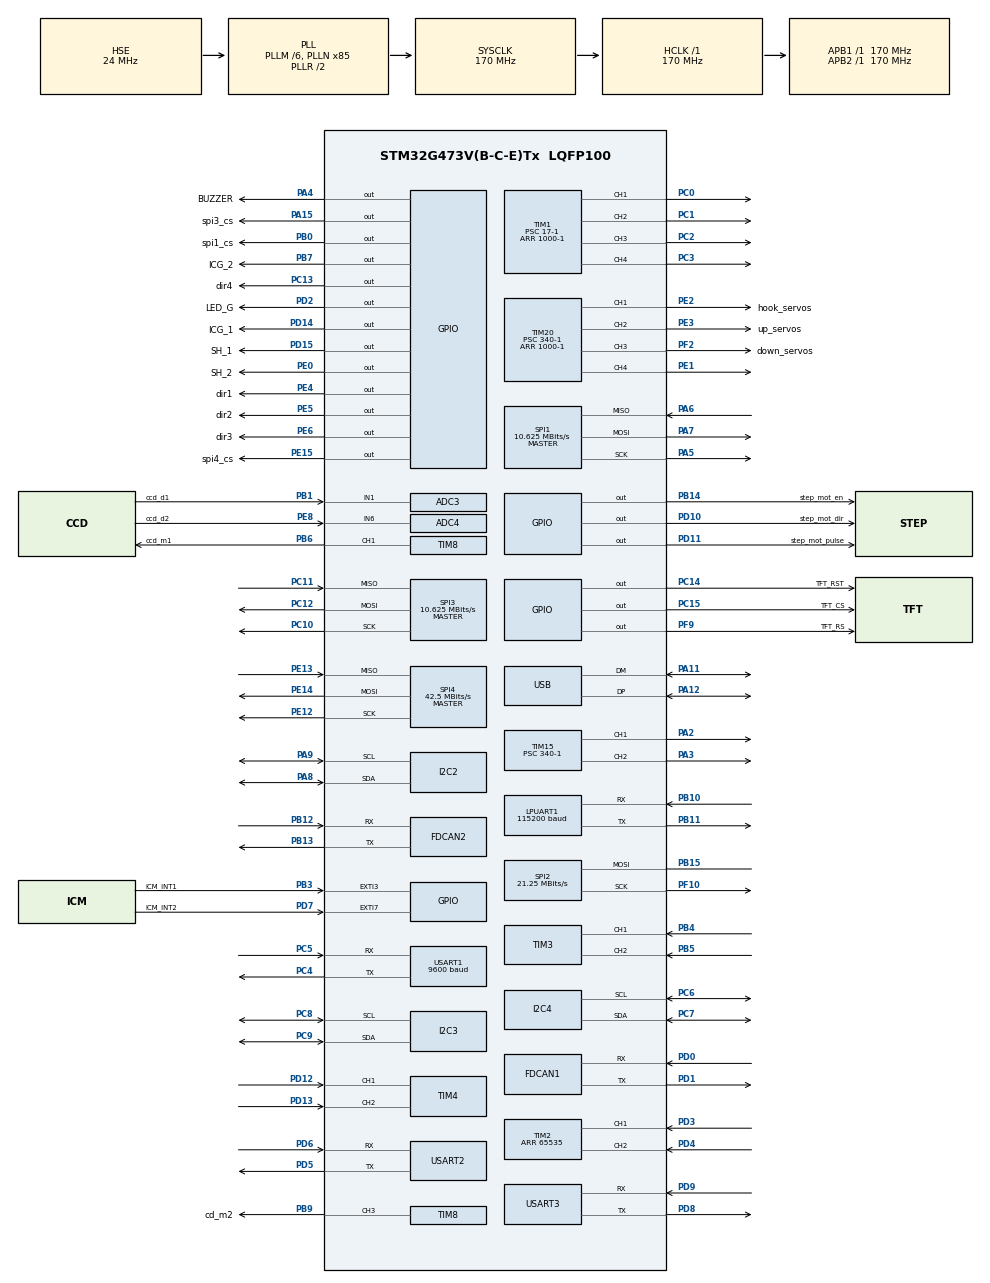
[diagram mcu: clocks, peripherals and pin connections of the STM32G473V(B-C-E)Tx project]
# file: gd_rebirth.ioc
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ADC3.Channel-0\#ChannelRegularConversion=ADC_CHANNEL_1
ADC3.DMAContinuousRequests=ENABLE
ADC3.ExternalTrigConv=ADC_EXTERNALTRIG_T7_TRGO
ADC3.NbrOfConversionFlag=1
ADC3.OffsetNumber-0\#ChannelRegularConversion=ADC_OFFSET_NONE
ADC3.Rank-0\#ChannelRegularConversion=1
ADC3.SamplingTime-0\#ChannelRegularConversion=ADC_SAMPLETIME_2CYCLES_5
ADC3.master=1
ADC4.Channel-0\#ChannelRegularConversion=ADC_CHANNEL_6
ADC4.ExternalTrigConv=ADC_EXTERNALTRIG_T7_TRGO
ADC4.NbrOfConversionFlag=1
ADC4.OffsetNumber-0\#ChannelRegularConversion=ADC_OFFSET_NONE
ADC4.Rank-0\#ChannelRegularConversion=1
ADC4.SamplingTime-0\#ChannelRegularConversion=ADC_SAMPLETIME_2CYCLES_5
Dma.ADC3.0.Direction=DMA_PERIPH_TO_MEMORY
Dma.ADC3.0.EventEnable=DISABLE
Dma.ADC3.0.Instance=DMA1_Channel1
Dma.ADC3.0.MemDataAlignment=DMA_MDATAALIGN_HALFWORD
Dma.ADC3.0.MemInc=DMA_MINC_ENABLE
Dma.ADC3.0.Mode=DMA_NORMAL
Dma.ADC3.0.PeriphDataAlignment=DMA_PDATAALIGN_HALFWORD
Dma.ADC3.0.PeriphInc=DMA_PINC_DISABLE
Dma.ADC3.0.Polarity=HAL_DMAMUX_REQ_GEN_RISING
Dma.ADC3.0.Priority=DMA_PRIORITY_LOW
Dma.ADC3.0.RequestNumber=1
Dma.ADC3.0.SignalID=NONE
Dma.ADC3.0.SyncEnable=DISABLE
Dma.ADC3.0.SyncPolarity=HAL_DMAMUX_SYNC_NO_EVENT
Dma.ADC3.0.SyncRequestNumber=1
Dma.ADC3.0.SyncSignalID=NONE
Dma.ADC4.1.Direction=DMA_PERIPH_TO_MEMORY
Dma.ADC4.1.EventEnable=DISABLE
Dma.ADC4.1.Instance=DMA1_Channel2
Dma.ADC4.1.MemDataAlignment=DMA_MDATAALIGN_HALFWORD
Dma.ADC4.1.MemInc=DMA_MINC_ENABLE
Dma.ADC4.1.Mode=DMA_NORMAL
Dma.ADC4.1.PeriphDataAlignment=DMA_PDATAALIGN_HALFWORD
Dma.ADC4.1.PeriphInc=DMA_PINC_DISABLE
Dma.ADC4.1.Polarity=HAL_DMAMUX_REQ_GEN_RISING
Dma.ADC4.1.Priority=DMA_PRIORITY_LOW
Dma.ADC4.1.RequestNumber=1
Dma.ADC4.1.SignalID=NONE
Dma.ADC4.1.SyncEnable=DISABLE
Dma.ADC4.1.SyncPolarity=HAL_DMAMUX_SYNC_NO_EVENT
Dma.ADC4.1.SyncRequestNumber=1
Dma.ADC4.1.SyncSignalID=NONE
Dma.Request0=ADC3
Dma.Request1=ADC4
Dma.Request2=USART2_RX
Dma.Request3=USART2_TX
Dma.USART2_RX.2.Direction=DMA_PERIPH_TO_MEMORY
Dma.USART2_RX.2.EventEnable=DISABLE
Dma.USART2_RX.2.Instance=DMA1_Channel3
Dma.USART2_RX.2.MemDataAlignment=DMA_MDATAALIGN_BYTE
Dma.USART2_RX.2.MemInc=DMA_MINC_ENABLE
Dma.USART2_RX.2.Mode=DMA_NORMAL
Dma.USART2_RX.2.PeriphDataAlignment=DMA_PDATAALIGN_BYTE
Dma.USART2_RX.2.PeriphInc=DMA_PINC_DISABLE
Dma.USART2_RX.2.Polarity=HAL_DMAMUX_REQ_GEN_RISING
Dma.USART2_RX.2.Priority=DMA_PRIORITY_LOW
Dma.USART2_RX.2.RequestNumber=1
Dma.USART2_RX.2.SignalID=NONE
Dma.USART2_RX.2.SyncEnable=DISABLE
Dma.USART2_RX.2.SyncPolarity=HAL_DMAMUX_SYNC_NO_EVENT
Dma.USART2_RX.2.SyncRequestNumber=1
Dma.USART2_RX.2.SyncSignalID=NONE
Dma.USART2_TX.3.Direction=DMA_MEMORY_TO_PERIPH
Dma.USART2_TX.3.EventEnable=DISABLE
Dma.USART2_TX.3.Instance=DMA1_Channel4
Dma.USART2_TX.3.MemDataAlignment=DMA_MDATAALIGN_BYTE
Dma.USART2_TX.3.MemInc=DMA_MINC_ENABLE
Dma.USART2_TX.3.Mode=DMA_NORMAL
Dma.USART2_TX.3.PeriphDataAlignment=DMA_PDATAALIGN_BYTE
Dma.USART2_TX.3.PeriphInc=DMA_PINC_DISABLE
Dma.USART2_TX.3.Polarity=HAL_DMAMUX_REQ_GEN_RISING
Dma.USART2_TX.3.Priority=DMA_PRIORITY_LOW
Dma.USART2_TX.3.RequestNumber=1
Dma.USART2_TX.3.SignalID=NONE
Dma.USART2_TX.3.SyncEnable=DISABLE
Dma.USART2_TX.3.SyncPolarity=HAL_DMAMUX_SYNC_NO_EVENT
Dma.USART2_TX.3.SyncRequestNumber=1
Dma.USART2_TX.3.SyncSignalID=NONE
FDCAN1.CalculateBaudRateNominal=1000000
FDCAN1.CalculateTimeBitNominal=1000
FDCAN1.CalculateTimeQuantumNominal=100.0
FDCAN1.NominalPrescaler=17
FDCAN1.NominalTimeSeg1=1
FDCAN1.NominalTimeSeg2=8
FDCAN2.CalculateBaudRateNominal=1000000
FDCAN2.CalculateTimeBitNominal=1000
FDCAN2.CalculateTimeQuantumNominal=100.0
FDCAN2.NominalPrescaler=17
FDCAN2.NominalTimeSeg2=8
FREERTOS.Tasks01=defaultTask,24,128,StartDefaultTask,Default,NULL,Dynamic,NULL,NULL
FREERTOS.configENABLE_FPU=1
I2C2.Timing=0x40B285C2
I2C3.Timing=0x40B285C2
I2C4.Timing=0x40B285C2
LPUART1.BaudRate=115200
Mcu.Family=STM32G4
Mcu.Name=STM32G473V(B-C-E)Tx
Mcu.Package=LQFP100
NVIC.DMA1_Channel1_IRQn=true\:5\:0\:false\:false\:true\:true\:false\:true\:true
NVIC.DMA1_Channel2_IRQn=true\:5\:0\:false\:false\:true\:true\:false\:true\:true
NVIC.DMA1_Channel3_IRQn=true\:5\:0\:false\:false\:true\:true\:false\:true\:true
NVIC.DMA1_Channel4_IRQn=true\:5\:0\:false\:false\:true\:true\:false\:true\:true
NVIC.FDCAN1_IT0_IRQn=true\:5\:0\:false\:false\:true\:true\:true\:true\:true
NVIC.FDCAN2_IT1_IRQn=true\:5\:0\:false\:false\:true\:true\:true\:true\:true
NVIC.PriorityGroup=NVIC_PRIORITYGROUP_4
NVIC.TIM1_TRG_COM_TIM17_IRQn=true\:5\:0\:false\:false\:true\:true\:true\:true\:true
NVIC.TIM1_UP_TIM16_IRQn=true\:5\:0\:false\:false\:true\:true\:true\:true\:true
NVIC.TIM5_IRQn=true\:5\:0\:false\:false\:true\:true\:true\:true\:true
NVIC.TIM6_DAC_IRQn=true\:5\:0\:false\:false\:true\:true\:true\:true\:true
NVIC.USART1_IRQn=true\:5\:0\:false\:false\:true\:true\:true\:true\:true
NVIC.USART2_IRQn=true\:5\:0\:false\:false\:true\:true\:true\:true\:true
PA0.Signal=S_TIM5_CH1
PA1.Signal=S_TIM5_CH2
PA11.Mode=Device
PA11.Signal=USB_DM
PA12.Mode=Device
PA12.Signal=USB_DP
PA13.Mode=Serial_Wire
PA13.Signal=SYS_JTMS-SWDIO
PA14.Mode=Serial_Wire
PA14.Signal=SYS_JTCK-SWCLK
PA15.GPIO_Label=spi3_cs
PA15.Signal=GPIO_Output
PA2.Signal=S_TIM15_CH1
PA3.Signal=S_TIM15_CH2
PA4.GPIO_Label=BUZZER
PA4.Signal=GPIO_Output
PA5.Mode=Full_Duplex_Master
PA5.Signal=SPI1_SCK
PA6.Mode=Full_Duplex_Master
PA6.Signal=SPI1_MISO
PA7.Mode=Full_Duplex_Master
PA7.Signal=SPI1_MOSI
PA8.Mode=I2C
PA8.Signal=I2C2_SDA
PA9.Mode=I2C
PA9.Signal=I2C2_SCL
PB0.GPIO_Label=spi1_cs
PB0.Signal=GPIO_Output
PB1.GPIO_Label=ccd_d1
PB1.Mode=IN1-Single-Ended
PB1.Signal=ADC3_IN1
PB10.Mode=Asynchronous
PB10.Signal=LPUART1_RX
PB11.Mode=Asynchronous
PB11.Signal=LPUART1_TX
PB12.Mode=FDCAN_Activate
PB12.Signal=FDCAN2_RX
PB13.Mode=FDCAN_Activate
PB13.Signal=FDCAN2_TX
PB14.GPIO_Label=step_mot_en
PB14.Signal=GPIO_Output
PB15.Mode=Simplex_Bidirectional_Master
PB15.Signal=SPI2_MOSI
PB3.GPIO_Label=ICM_INT1
PB3.Signal=GPXTI3
PB4.GPIO_PuPd=GPIO_PULLUP
PB4.Signal=S_TIM3_CH1
PB5.GPIO_PuPd=GPIO_PULLUP
PB5.Signal=S_TIM3_CH2
PB6.GPIO_Label=ccd_m1
PB6.Signal=S_TIM8_CH1
PB7.GPIO_Label=ICG_2
PB7.Signal=GPIO_Output
PB9.GPIO_Label=cd_m2
PB9.Signal=S_TIM8_CH3
PC0.Signal=S_TIM1_CH1
PC1.Signal=S_TIM1_CH2
PC10.Mode=Full_Duplex_Master
PC10.Signal=SPI3_SCK
PC11.Mode=Full_Duplex_Master
PC11.Signal=SPI3_MISO
PC12.Mode=Full_Duplex_Master
PC12.Signal=SPI3_MOSI
PC13.GPIO_Label=dir4
PC13.Signal=GPIO_Output
PC14-OSC32_IN.GPIO_Label=TFT_RST
PC14-OSC32_IN.Signal=GPIO_Output
PC15-OSC32_OUT.GPIO_Label=TFT_CS
PC15-OSC32_OUT.Signal=GPIO_Output
PC2.Signal=S_TIM1_CH3
PC3.Signal=S_TIM1_CH4
PC4.Mode=Asynchronous
PC4.Signal=USART1_TX
PC5.Mode=Asynchronous
PC5.Signal=USART1_RX
PC6.Mode=I2C
PC6.Signal=I2C4_SCL
PC7.Mode=I2C
PC7.Signal=I2C4_SDA
PC8.Mode=I2C
PC8.Signal=I2C3_SCL
PC9.Mode=I2C
PC9.Signal=I2C3_SDA
PD0.Mode=FDCAN_Activate
PD0.Signal=FDCAN1_RX
PD1.Mode=FDCAN_Activate
PD1.Signal=FDCAN1_TX
PD10.GPIO_Label=step_mot_dir
PD10.Signal=GPIO_Output
PD11.GPIO_Label=step_mot_pulse
PD11.Signal=GPIO_Output
PD12.Signal=S_TIM4_CH1
PD13.Signal=S_TIM4_CH2
PD14.GPIO_Label=ICG_1
PD14.Signal=GPIO_Output
PD15.GPIO_Label=SH_1
PD15.Signal=GPIO_Output
PD2.GPIO_Label=LED_G
PD2.GPIO_PuPd=GPIO_PULLDOWN
PD2.Signal=GPIO_Output
PD3.GPIO_PuPd=GPIO_PULLUP
PD3.Signal=S_TIM2_CH1
PD4.GPIO_PuPd=GPIO_PULLUP
PD4.Signal=S_TIM2_CH2
PD5.Mode=Asynchronous
PD5.Signal=USART2_TX
PD6.Mode=Asynchronous
PD6.Signal=USART2_RX
PD7.GPIO_Label=ICM_INT2
PD7.Signal=GPXTI7
PD8.Mode=Asynchronous
PD8.Signal=USART3_TX
PD9.Mode=Asynchronous
PD9.Signal=USART3_RX
PE0.GPIO_Label=SH_2
PE0.Signal=GPIO_Output
PE1.Signal=S_TIM20_CH4
PE12.Mode=Full_Duplex_Master
PE12.Signal=SPI4_SCK
PE13.Mode=Full_Duplex_Master
PE13.Signal=SPI4_MISO
PE14.Mode=Full_Duplex_Master
PE14.Signal=SPI4_MOSI
PE15.GPIO_Label=spi4_cs
PE15.Signal=GPIO_Output
PE2.GPIO_Label=hook_servos
PE2.Signal=S_TIM20_CH1
PE3.GPIO_Label=up_servos
PE3.Signal=S_TIM20_CH2
PE4.GPIO_Label=dir1
PE4.Signal=GPIO_Output
PE5.GPIO_Label=dir2
PE5.Signal=GPIO_Output
PE6.GPIO_Label=dir3
PE6.Signal=GPIO_Output
PE8.GPIO_Label=ccd_d2
PE8.Mode=IN6-Single-Ended
PE8.Signal=ADC4_IN6
PF0-OSC_IN.Mode=HSE-External-Oscillator
PF0-OSC_IN.Signal=RCC_OSC_IN
PF1-OSC_OUT.Mode=HSE-External-Oscillator
PF1-OSC_OUT.Signal=RCC_OSC_OUT
PF10.Mode=Simplex_Bidirectional_Master
PF10.Signal=SPI2_SCK
PF2.GPIO_Label=down_servos
PF2.Signal=S_TIM20_CH3
PF9.GPIO_Label=TFT_RS
PF9.Signal=GPIO_Output
ProjectManager.HeapSize=0x1000
ProjectManager.StackSize=0x800
ProjectManager.TargetToolchain=MDK-ARM V5.32
RCC.ADC12Freq_Value=170000000
RCC.ADC345Freq_Value=170000000
RCC.AHBFreq_Value=170000000
RCC.APB1Freq_Value=170000000
RCC.APB1TimFreq_Value=170000000
RCC.APB2Freq_Value=170000000
RCC.APB2TimFreq_Value=170000000
RCC.CK48CLockSelection=RCC_USBCLKSOURCE_HSI48
RCC.CortexFreq_Value=170000000
RCC.EXTERNAL_CLOCK_VALUE=12288000
RCC.HCLKFreq_Value=170000000
RCC.HSE_VALUE=24000000
RCC.HSI48_VALUE=48000000
RCC.HSI_VALUE=16000000
RCC.LSE_VALUE=32768
RCC.PLLM=RCC_PLLM_DIV6
RCC.PLLN=85
RCC.PLLSourceVirtual=RCC_PLLSOURCE_HSE
RCC.SYSCLKFreq_VALUE=170000000
RCC.SYSCLKSource=RCC_SYSCLKSOURCE_PLLCLK
RCC.USBFreq_Value=48000000
RCC.VCOOutputFreq_Value=340000000
SH.S_TIM15_CH1.0=TIM15_CH1,PWM Generation1 CH1
SH.S_TIM15_CH2.0=TIM15_CH2,PWM Generation2 CH2
SH.S_TIM1_CH1.0=TIM1_CH1,PWM Generation1 CH1
SH.S_TIM1_CH2.0=TIM1_CH2,PWM Generation2 CH2
SH.S_TIM1_CH3.0=TIM1_CH3,PWM Generation3 CH3
SH.S_TIM1_CH4.0=TIM1_CH4,PWM Generation4 CH4
SH.S_TIM20_CH1.0=TIM20_CH1,PWM Generation1 CH1
SH.S_TIM20_CH2.0=TIM20_CH2,PWM Generation2 CH2
SH.S_TIM20_CH3.0=TIM20_CH3,PWM Generation3 CH3
SH.S_TIM20_CH4.0=TIM20_CH4,PWM Generation4 CH4
SH.S_TIM2_CH1.0=TIM2_CH1,Encoder_Interface
SH.S_TIM2_CH2.0=TIM2_CH2,Encoder_Interface
SH.S_TIM3_CH1.0=TIM3_CH1,Encoder_Interface
SH.S_TIM3_CH2.0=TIM3_CH2,Encoder_Interface
SH.S_TIM4_CH1.0=TIM4_CH1,Encoder_Interface
SH.S_TIM4_CH2.0=TIM4_CH2,Encoder_Interface
SH.S_TIM5_CH1.0=TIM5_CH1
SH.S_TIM5_CH2.0=TIM5_CH2
SH.S_TIM8_CH1.0=TIM8_CH1,PWM Generation1 CH1
SH.S_TIM8_CH3.0=TIM8_CH3,PWM Generation3 CH3
SPI1.BaudRatePrescaler=SPI_BAUDRATEPRESCALER_16
SPI1.CalculateBaudRate=10.625 MBits/s
SPI1.Direction=SPI_DIRECTION_2LINES
SPI1.Mode=SPI_MODE_MASTER
SPI1.VirtualType=VM_MASTER
SPI2.BaudRatePrescaler=SPI_BAUDRATEPRESCALER_8
SPI2.CalculateBaudRate=21.25 MBits/s
SPI2.Direction=SPI_DIRECTION_1LINE
SPI2.Mode=SPI_MODE_MASTER
SPI2.VirtualType=VM_MASTER
SPI3.BaudRatePrescaler=SPI_BAUDRATEPRESCALER_16
SPI3.CalculateBaudRate=10.625 MBits/s
SPI3.Direction=SPI_DIRECTION_2LINES
SPI3.Mode=SPI_MODE_MASTER
SPI3.VirtualType=VM_MASTER
SPI4.BaudRatePrescaler=SPI_BAUDRATEPRESCALER_4
SPI4.CalculateBaudRate=42.5 MBits/s
SPI4.Direction=SPI_DIRECTION_2LINES
SPI4.Mode=SPI_MODE_MASTER
SPI4.VirtualType=VM_MASTER
TIM1.AutoReloadPreload=TIM_AUTORELOAD_PRELOAD_ENABLE
TIM1.Channel-PWM\ Generation1\ CH1=TIM_CHANNEL_1
TIM1.Channel-PWM\ Generation2\ CH2=TIM_CHANNEL_2
TIM1.Channel-PWM\ Generation3\ CH3=TIM_CHANNEL_3
TIM1.Channel-PWM\ Generation4\ CH4=TIM_CHANNEL_4
TIM1.PeriodNoDither=1000-1
TIM1.Prescaler=17-1
TIM15.AutoReloadPreload=TIM_AUTORELOAD_PRELOAD_ENABLE
TIM15.Channel-PWM\ Generation1\ CH1=TIM_CHANNEL_1
TIM15.Channel-PWM\ Generation2\ CH2=TIM_CHANNEL_2
TIM15.PeriodNoDither=1000-1
TIM15.Prescaler=340-1
TIM16.AutoReloadPreload=TIM_AUTORELOAD_PRELOAD_ENABLE
TIM16.PeriodNoDither=1000-1
TIM16.Prescaler=170-1
TIM17.AutoReloadPreload=TIM_AUTORELOAD_PRELOAD_ENABLE
TIM17.PeriodNoDither=5000-1
TIM17.Prescaler=170-1
TIM2.EncoderMode=TIM_ENCODERMODE_TI12
TIM2.IC1Filter=2
TIM2.IC2Filter=2
TIM2.PeriodNoDither=65535
TIM20.AutoReloadPreload=TIM_AUTORELOAD_PRELOAD_ENABLE
TIM20.Channel-PWM\ Generation1\ CH1=TIM_CHANNEL_1
TIM20.Channel-PWM\ Generation2\ CH2=TIM_CHANNEL_2
TIM20.Channel-PWM\ Generation3\ CH3=TIM_CHANNEL_3
TIM20.Channel-PWM\ Generation4\ CH4=TIM_CHANNEL_4
TIM20.PeriodNoDither=1000-1
TIM20.Prescaler=340-1
TIM3.EncoderMode=TIM_ENCODERMODE_TI12
TIM3.IC1Filter=0
TIM3.IC2Filter=0
TIM5.AutoReloadPreload=TIM_AUTORELOAD_PRELOAD_ENABLE
TIM5.PeriodNoDither=170-1
TIM5.Prescaler=1-1
TIM6.PeriodNoDither=170-1
TIM6.Prescaler=3000-1
TIM7.PeriodNoDither=120-1
TIM7.Prescaler=2-1
TIM7.TIM_MasterOutputTrigger=TIM_TRGO_UPDATE
TIM8.AutoReloadPreload=TIM_AUTORELOAD_PRELOAD_DISABLE
TIM8.Channel-PWM\ Generation1\ CH1=TIM_CHANNEL_1
TIM8.Channel-PWM\ Generation3\ CH3=TIM_CHANNEL_3
TIM8.PeriodNoDither=120-1
TIM8.Prescaler=1-1
USART1.BaudRate=9600
USART1.VirtualMode-Asynchronous=VM_ASYNC
USART2.VirtualMode-Asynchronous=VM_ASYNC
USART3.VirtualMode-Asynchronous=VM_ASYNC
VP_FREERTOS_VS_CMSIS_V2.Mode=CMSIS_V2
VP_SYS_VS_DBSignals.Mode=DisableDeadBatterySignals
VP_TIM15_VS_ClockSourceINT.Mode=Internal
VP_TIM16_VS_ClockSourceINT.Mode=Enable_Timer
VP_TIM17_VS_ClockSourceINT.Mode=Enable_Timer
VP_TIM1_VS_ClockSourceINT.Mode=Internal
VP_TIM20_VS_ClockSourceINT.Mode=Internal
VP_TIM5_VS_ClockSourceINT.Mode=Internal
VP_TIM6_VS_ClockSourceINT.Mode=Enable_Timer
VP_TIM7_VS_ClockSourceINT.Mode=Enable_Timer
VP_TIM8_VS_ClockSourceINT.Mode=Internal
board=custom

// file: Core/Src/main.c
/* USER CODE BEGIN Header */
/**
 ******************************************************************************
 * @file           : main.c
 * @brief          : Main program body
 ******************************************************************************
 * @attention
 *
 * Copyright (c) 2025 STMicroelectronics.
 * All rights reserved.
 *
 * This software is licensed under terms that can be found in the LICENSE file
 * in the root directory of this software component.
 * If no LICENSE file comes with this software, it is provided AS-IS.
 *
 ******************************************************************************
 */
/* USER CODE END Header */
#include "main.h"
#include "cmsis_os.h"
#include "adc.h"
#include "dma.h"
#include "fdcan.h"
#include "i2c.h"
#include "usart.h"
#include "spi.h"
#include "tim.h"
#include "usb.h"
#include "gpio.h"

/* USER CODE BEGIN Includes */
#include "tcs230.h"
#include "bsp_usart.h"
#include "tcd1103.h"
#include "dc_motor.h"
#include "gray.h"
#include "mainwork.h"

int goods_color = 90;
static uint32_t fac_us = 0; // us延时倍乘数
USARTInstance uart2 = {0};
void usart2_callback(void)
{
}
USART_Init_Config_s usart2_config = {
    .recv_buff_size = 64,
    .usart_handle = &huart2,
    .module_callback = usart2_callback,
};
/* USER CODE END Includes */

void SystemClock_Config(void);
void MX_FREERTOS_Init(void);
/* USER CODE BEGIN PFP */
static void delay_us(uint32_t nus)
{
  uint32_t ticks;
  uint32_t told, tnow, tcnt = 0;
  uint32_t reload = SysTick->LOAD; // LOAD的值
  ticks = nus * fac_us;            // 需要的节拍数
  told = SysTick->VAL;             // 刚进入时的计数器值
  while (1)
  {
    tnow = SysTick->VAL;
    if (tnow != told)
    {
      if (tnow < told)
        tcnt += told - tnow; // 这里注意一下SYSTICK是一个递减的计数器就可以了.
      else
        tcnt += reload - tnow + told;
      told = tnow;
      if (tcnt >= ticks)
        break; // 时间超过/等于要延迟的时间,则退出.
    }
  };
}
void HAL_TIM_PeriodElapsedCallback(TIM_HandleTypeDef *htim)
{
  if (htim->Instance == htim6.Instance)
  {
    if (HAL_GetTick() - icg_flag >= 10)
    {
      HAL_GPIO_WritePin(ICG_1_GPIO_Port, ICG_1_Pin, 1);
      HAL_GPIO_WritePin(SH_1_GPIO_Port, SH_1_Pin, 0);
      delay_us(2);
      HAL_GPIO_WritePin(SH_1_GPIO_Port, SH_1_Pin, 1);
      delay_us(4);
      HAL_GPIO_WritePin(ICG_1_GPIO_Port, ICG_1_Pin, 0);
      HAL_ADC_Start_DMA(&hadc3, (uint32_t *)ccd_rawdata, 1546);
      icg_flag = HAL_GetTick();
    }
    else
    {
      HAL_GPIO_WritePin(SH_1_GPIO_Port, SH_1_Pin, 0);
      delay_us(2);
      HAL_GPIO_WritePin(SH_1_GPIO_Port, SH_1_Pin, 1);
      delay_us(4);
    }
  }
}
/* USER CODE END PFP */

int main(void)
{

  /* MCU Configuration--------------------------------------------------------*/

  /* Reset of all peripherals, Initializes the Flash interface and the Systick. */
  HAL_Init();

  /* Configure the system clock */
  SystemClock_Config();

  /* Initialize all configured peripherals */
  MX_GPIO_Init();
  MX_DMA_Init();
  MX_FDCAN1_Init();
  MX_FDCAN2_Init();
  MX_I2C2_Init();
  MX_I2C3_Init();
  MX_LPUART1_UART_Init();
  MX_USART1_UART_Init();
  MX_USART2_UART_Init();
  MX_USART3_UART_Init();
  MX_SPI1_Init();
  MX_SPI2_Init();
  MX_SPI3_Init();
  MX_TIM1_Init();
  MX_TIM3_Init();
  MX_TIM5_Init();
  MX_USB_PCD_Init();
  MX_SPI4_Init();
  MX_TIM2_Init();
  MX_TIM4_Init();
  MX_TIM8_Init();
  MX_ADC3_Init();
  MX_TIM6_Init();
  MX_TIM7_Init();
  MX_TIM15_Init();
  MX_TIM16_Init();
  MX_TIM17_Init();
  MX_TIM20_Init();
  MX_ADC4_Init();
  MX_I2C4_Init();
  /* USER CODE BEGIN 2 */

  // 指示灯
  HAL_GPIO_WritePin(LED_G_GPIO_Port, LED_G_Pin, 0);
  // 电机配置
	//重要：encoder对应引脚记得上拉
  IncEncoderInit(&encoder_0, 0, 1);
  IncEncoderInit(&encoder_1, 1, 1);
  PID_struct_init(&pid_0, POSITION_PID, 800, 200, 50, 1, 0);
  PID_struct_init(&pid_1, POSITION_PID, 800, 200, 50, 1,0);
  DCMotorInit(&motor_0, 0, 1, &encoder_0, &pid_0);
  DCMotorInit(&motor_1, 1, 0, &encoder_1, &pid_1);
  //舵机配置
  HAL_TIM_PWM_Start(&htim20,TIM_CHANNEL_1);
	 HAL_TIM_PWM_Start(&htim20,TIM_CHANNEL_2);
	  HAL_TIM_PWM_Start(&htim20,TIM_CHANNEL_3);

  // debug串口
  USARTRegister(&uart2, &usart2_config);
  memset(uart2.recv_buff, 0, uart2.recv_buff_size);

//普通灰度
	while(Ping())
	{
	HAL_Delay(5);
	}

  // tcd1103配置
  HAL_TIM_Base_Start_IT(&htim6);
  HAL_TIM_Base_Start(&htim7);
  __HAL_TIM_SetCompare(&htim8, TIM_CHANNEL_1, 60);
  // 定时器16开启，1ms的更新中断
  HAL_TIM_Base_Start_IT(&htim16);
	// 定时器17开启，5ms的更新中断
  HAL_TIM_Base_Start_IT(&htim17);

  // 定时器5开启，1us的更新中断，原本是电机的encoder读入，现在用作ccd的严格时序运行
  HAL_TIM_Base_Start_IT(&htim5);
main_work();
  /* USER CODE END 2 */

  /* Init scheduler */
  osKernelInitialize();  /* Call init function for freertos objects (in cmsis_os2.c) */
  MX_FREERTOS_Init();

  /* Start scheduler */
  osKernelStart();

  /* We should never get here as control is now taken by the scheduler */

  /* Infinite loop */
  while (1)
  {

  }
}

void SystemClock_Config(void)
{
  RCC_OscInitTypeDef RCC_OscInitStruct = {0};
  RCC_ClkInitTypeDef RCC_ClkInitStruct = {0};

  /** Configure the main internal regulator output voltage
  */
  HAL_PWREx_ControlVoltageScaling(PWR_REGULATOR_VOLTAGE_SCALE1_BOOST);

  /** Initializes the RCC Oscillators according to the specified parameters
  * in the RCC_OscInitTypeDef structure.
  */
  RCC_OscInitStruct.OscillatorType = RCC_OSCILLATORTYPE_HSI48|RCC_OSCILLATORTYPE_HSE;
  RCC_OscInitStruct.HSEState = RCC_HSE_ON;
  RCC_OscInitStruct.HSI48State = RCC_HSI48_ON;
  RCC_OscInitStruct.PLL.PLLState = RCC_PLL_ON;
  RCC_OscInitStruct.PLL.PLLSource = RCC_PLLSOURCE_HSE;
  RCC_OscInitStruct.PLL.PLLM = RCC_PLLM_DIV6;
  RCC_OscInitStruct.PLL.PLLN = 85;
  RCC_OscInitStruct.PLL.PLLP = RCC_PLLP_DIV2;
  RCC_OscInitStruct.PLL.PLLQ = RCC_PLLQ_DIV2;
  RCC_OscInitStruct.PLL.PLLR = RCC_PLLR_DIV2;
  if (HAL_RCC_OscConfig(&RCC_OscInitStruct) != HAL_OK)
  {
    Error_Handler();
  }

  /** Initializes the CPU, AHB and APB buses clocks
  */
  RCC_ClkInitStruct.ClockType = RCC_CLOCKTYPE_HCLK|RCC_CLOCKTYPE_SYSCLK
                              |RCC_CLOCKTYPE_PCLK1|RCC_CLOCKTYPE_PCLK2;
  RCC_ClkInitStruct.SYSCLKSource = RCC_SYSCLKSOURCE_PLLCLK;
  RCC_ClkInitStruct.AHBCLKDivider = RCC_SYSCLK_DIV1;
  RCC_ClkInitStruct.APB1CLKDivider = RCC_HCLK_DIV1;
  RCC_ClkInitStruct.APB2CLKDivider = RCC_HCLK_DIV1;

  if (HAL_RCC_ClockConfig(&RCC_ClkInitStruct, FLASH_LATENCY_4) != HAL_OK)
  {
    Error_Handler();
  }
}

void Error_Handler(void)
{
  __disable_irq();
  while (1)
  {
  }
}
